# CPSW0_NUSS_CPINT register map
Vendor: Texas Instruments
Peripheral module from a debugger description file (folder J7VCL).
Registers are 32-bit, read-only, reset values left out (the file's numbers can be read two ways) unless marked. A register's access mark holds for its fields unless they carry their own. Offsets are as the file gives them; lines under a group give offsets from that group; [hi:lo] are bit positions; {n}, {i} and the like mark numbered series; 'fields as' and 'values as' point back to an identical list; <NAME> marks a mode.

## CPSW0_NUSS_CPINT
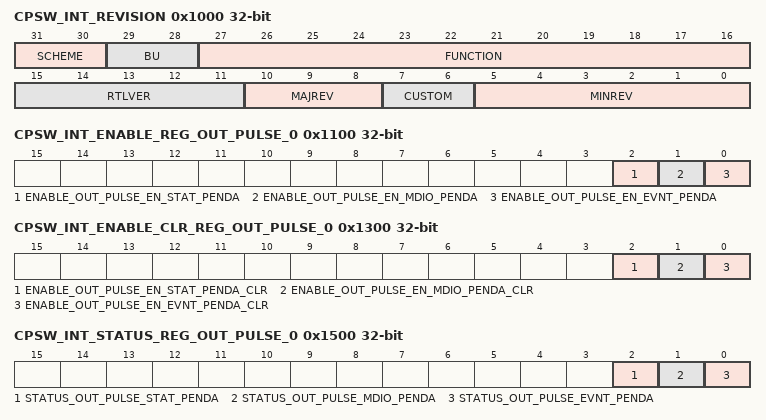
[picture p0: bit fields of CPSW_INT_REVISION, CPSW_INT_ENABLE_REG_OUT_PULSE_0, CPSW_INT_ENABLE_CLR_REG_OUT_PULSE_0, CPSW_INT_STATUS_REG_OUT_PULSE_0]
0x1000 CPSW_INT_REVISION — Register.
  [31:30] SCHEME
  [29:28] BU
  [27:16] FUNCTION — Module ID
  [15:11] RTLVER — RTL revisions
  [10:8] MAJREV — Major revision
  [7:6] CUSTOM — Custom revision
  [5:0] MINREV — Minor revision
0x1010 CPSW_INT_EOI_REG rw — End of Interrupt Register. The EOI register is used to re-trigger the pulse interrupt signal to ensure that any nested interrupt events are serviced. The software interrupt handler must write to the EOI register at the end of the current interrupt processing routine, so that new events can re-trigger the pulse interrupt signal again. For level interrupt signals the EOI register is not functional and must not be used.
  [7:0] EOI_VECTOR — End of Interrupt Vector.
0x1014 CPSW_INT_INTR_VECTOR_REG — Interrupt Vector Register.
  [31:0] INTR_VECTOR — Interrupt Vector Register
0x1100 CPSW_INT_ENABLE_REG_OUT_PULSE_0 access not given — Enable Register 0.
  [2] ENABLE_OUT_PULSE_EN_STAT_PENDA — Enable Set for out_pulse_en_stat_penda. (access RW1S)
  [1] ENABLE_OUT_PULSE_EN_MDIO_PENDA — Enable Set for out_pulse_en_mdio_penda. (access RW1S)
  [0] ENABLE_OUT_PULSE_EN_EVNT_PENDA — Enable Set for out_pulse_en_evnt_penda. (access RW1S)
0x1300 CPSW_INT_ENABLE_CLR_REG_OUT_PULSE_0 access not given — Enable Clear Register 0.
  [2] ENABLE_OUT_PULSE_EN_STAT_PENDA_CLR — Enable Clear for out_pulse_en_stat_penda. (access RW1C)
  [1] ENABLE_OUT_PULSE_EN_MDIO_PENDA_CLR — Enable Clear for out_pulse_en_mdio_penda. (access RW1C)
  [0] ENABLE_OUT_PULSE_EN_EVNT_PENDA_CLR — Enable Clear for out_pulse_en_evnt_penda. (access RW1C)
0x1500 CPSW_INT_STATUS_REG_OUT_PULSE_0 — Status Register 0.
  [2] STATUS_OUT_PULSE_STAT_PENDA — Status for out_pulse_en_stat_penda.
  [1] STATUS_OUT_PULSE_MDIO_PENDA — Status for out_pulse_en_mdio_penda.
  [0] STATUS_OUT_PULSE_EVNT_PENDA — Status for out_pulse_en_evnt_penda.
0x1A80 CPSW_INT_INTR_VECTOR_REG_OUT_PULSE — Interrupt Vector for out_pulse.
  [31:0] INTR_VECTOR_OUT_PULSE — Interrupt Vector.
